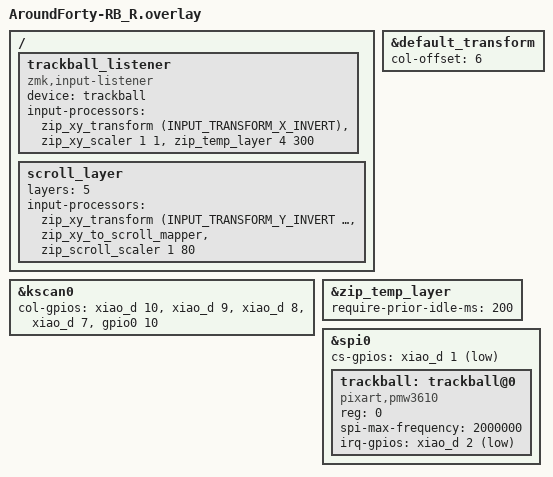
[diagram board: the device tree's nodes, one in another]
#include "AroundForty-RB.dtsi"

#include <dt-bindings/zmk/pointing.h>
#include <dt-bindings/zmk/input_transform.h>

#include <input/processors.dtsi>

#include <zephyr/dt-bindings/input/input-event-codes.h>

&default_transform {
    col-offset = <6>;
};

&kscan0 {
    col-gpios
        = <&xiao_d 10 GPIO_ACTIVE_HIGH>
        , <&xiao_d 9 GPIO_ACTIVE_HIGH>
        , <&xiao_d 8 GPIO_ACTIVE_HIGH>
        , <&xiao_d 7 GPIO_ACTIVE_HIGH>
        , <&gpio0 10 GPIO_ACTIVE_HIGH>;
};

&zip_temp_layer {
    require-prior-idle-ms = <200>;
};

&spi0 {
    status = "okay";

    cs-gpios = <&xiao_d 1 GPIO_ACTIVE_LOW>;

    trackball: trackball@0 {
        compatible = "pixart,pmw3610";

        reg = <0>;

        spi-max-frequency = <2000000>;

        irq-gpios = <&xiao_d 2 (GPIO_ACTIVE_LOW | GPIO_PULL_UP)>;

        status = "okay";
    };
};

/ {
    trackball_listener: trackball_listener {
        compatible = "zmk,input-listener";

        device = <&trackball>;

        input-processors =
            <&zip_xy_transform (INPUT_TRANSFORM_X_INVERT)>,

            /* カーソル速度 */
            <&zip_xy_scaler 1 1>,

            /* Auto mouse layer */
            <&zip_temp_layer 4 300>;
    };

    scroll_layer {
        layers = <5>;

        input-processors =
            <&zip_xy_transform
                (INPUT_TRANSFORM_Y_INVERT |
                 INPUT_TRANSFORM_X_INVERT)>,

            <&zip_xy_to_scroll_mapper>,

            /* スクロール速度 */
            <&zip_scroll_scaler 1 80>;
    };
};
